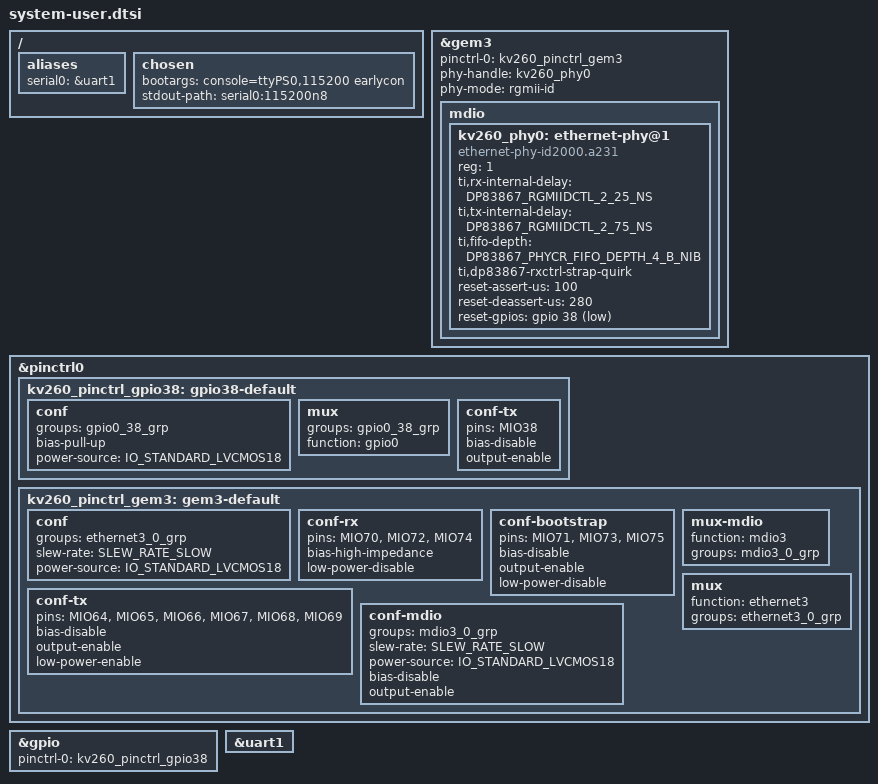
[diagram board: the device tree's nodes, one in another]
#include <dt-bindings/gpio/gpio.h>
#include <dt-bindings/net/ti-dp83867.h>
#include <dt-bindings/pinctrl/pinctrl-zynqmp.h>

/include/ "system-conf.dtsi"

/ {
    aliases {
        serial0 = &uart1;
    };

    chosen {
        bootargs = "console=ttyPS0,115200 earlycon";
        stdout-path = "serial0:115200n8";
    };
};

/* KV260 carrier Ethernet: GEM3 -> TI DP83867 PHY */
&gem3 {
    /delete-property/ local-mac-address;

    status = "okay";

    pinctrl-names = "default";
    pinctrl-0 = <&kv260_pinctrl_gem3>;

    phy-handle = <&kv260_phy0>;
    phy-mode = "rgmii-id";

    mdio {
        #address-cells = <1>;
        #size-cells = <0>;

        kv260_phy0: ethernet-phy@1 {
            #phy-cells = <1>;
            reg = <1>;

            compatible = "ethernet-phy-id2000.a231";

            ti,rx-internal-delay = <DP83867_RGMIIDCTL_2_25_NS>;
            ti,tx-internal-delay = <DP83867_RGMIIDCTL_2_75_NS>;
            ti,fifo-depth = <DP83867_PHYCR_FIFO_DEPTH_4_B_NIB>;
            ti,dp83867-rxctrl-strap-quirk;

            reset-assert-us = <100>;
            reset-deassert-us = <280>;
            reset-gpios = <&gpio 38 GPIO_ACTIVE_LOW>;
        };
    };
};

/* GPIO38 is the KV260 Ethernet PHY reset */
&pinctrl0 {
    status = "okay";

    kv260_pinctrl_gpio38: gpio38-default {
        conf {
            groups = "gpio0_38_grp";
            bias-pull-up;
            power-source = <IO_STANDARD_LVCMOS18>;
        };

        mux {
            groups = "gpio0_38_grp";
            function = "gpio0";
        };

        conf-tx {
            pins = "MIO38";
            bias-disable;
            output-enable;
        };
    };

    kv260_pinctrl_gem3: gem3-default {
        conf {
            groups = "ethernet3_0_grp";
            slew-rate = <SLEW_RATE_SLOW>;
            power-source = <IO_STANDARD_LVCMOS18>;
        };

        conf-rx {
            pins = "MIO70", "MIO72", "MIO74";
            bias-high-impedance;
            low-power-disable;
        };

        conf-bootstrap {
            pins = "MIO71", "MIO73", "MIO75";
            bias-disable;
            output-enable;
            low-power-disable;
        };

        conf-tx {
            pins = "MIO64", "MIO65", "MIO66",
                   "MIO67", "MIO68", "MIO69";
            bias-disable;
            output-enable;
            low-power-enable;
        };

        conf-mdio {
            groups = "mdio3_0_grp";
            slew-rate = <SLEW_RATE_SLOW>;
            power-source = <IO_STANDARD_LVCMOS18>;
            bias-disable;
            output-enable;
        };

        mux-mdio {
            function = "mdio3";
            groups = "mdio3_0_grp";
        };

        mux {
            function = "ethernet3";
            groups = "ethernet3_0_grp";
        };
    };
};

&gpio {
    status = "okay";
    pinctrl-names = "default";
    pinctrl-0 = <&kv260_pinctrl_gpio38>;
};

&uart1 {
    status = "okay";
};
